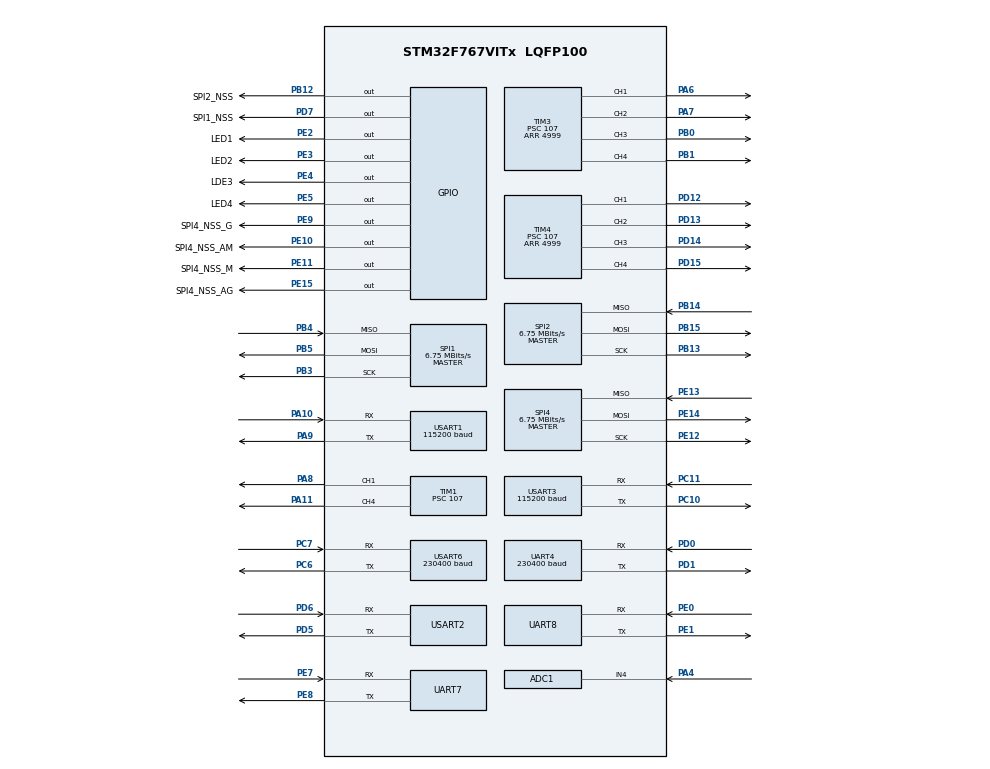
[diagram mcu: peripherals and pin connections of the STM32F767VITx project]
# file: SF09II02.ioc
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ADC1.Channel-0\#ChannelRegularConversion=ADC_CHANNEL_4
ADC1.NbrOfConversionFlag=1
ADC1.Rank-0\#ChannelRegularConversion=1
ADC1.SamplingTime-0\#ChannelRegularConversion=ADC_SAMPLETIME_3CYCLES
ADC1.master=1
Dma.ADC1.0.Direction=DMA_PERIPH_TO_MEMORY
Dma.ADC1.0.FIFOMode=DMA_FIFOMODE_DISABLE
Dma.ADC1.0.Instance=DMA2_Stream0
Dma.ADC1.0.MemDataAlignment=DMA_MDATAALIGN_HALFWORD
Dma.ADC1.0.MemInc=DMA_MINC_ENABLE
Dma.ADC1.0.Mode=DMA_NORMAL
Dma.ADC1.0.PeriphDataAlignment=DMA_PDATAALIGN_HALFWORD
Dma.ADC1.0.PeriphInc=DMA_PINC_DISABLE
Dma.ADC1.0.Priority=DMA_PRIORITY_LOW
Dma.Request0=ADC1
Dma.Request1=UART8_RX
Dma.Request10=UART4_RX
Dma.Request11=UART4_TX
Dma.Request2=USART1_RX
Dma.Request3=USART2_RX
Dma.Request4=USART3_RX
Dma.Request5=USART3_TX
Dma.Request6=USART6_RX
Dma.Request7=USART6_TX
Dma.Request8=UART8_TX
Dma.Request9=USART1_TX
Dma.UART4_RX.10.Direction=DMA_PERIPH_TO_MEMORY
Dma.UART4_RX.10.FIFOMode=DMA_FIFOMODE_DISABLE
Dma.UART4_RX.10.Instance=DMA1_Stream2
Dma.UART4_RX.10.MemDataAlignment=DMA_MDATAALIGN_BYTE
Dma.UART4_RX.10.MemInc=DMA_MINC_ENABLE
Dma.UART4_RX.10.Mode=DMA_NORMAL
Dma.UART4_RX.10.PeriphDataAlignment=DMA_PDATAALIGN_BYTE
Dma.UART4_RX.10.PeriphInc=DMA_PINC_DISABLE
Dma.UART4_RX.10.Priority=DMA_PRIORITY_LOW
Dma.UART4_TX.11.Direction=DMA_MEMORY_TO_PERIPH
Dma.UART4_TX.11.FIFOMode=DMA_FIFOMODE_DISABLE
Dma.UART4_TX.11.Instance=DMA1_Stream4
Dma.UART4_TX.11.MemDataAlignment=DMA_MDATAALIGN_BYTE
Dma.UART4_TX.11.MemInc=DMA_MINC_ENABLE
Dma.UART4_TX.11.Mode=DMA_NORMAL
Dma.UART4_TX.11.PeriphDataAlignment=DMA_PDATAALIGN_BYTE
Dma.UART4_TX.11.PeriphInc=DMA_PINC_DISABLE
Dma.UART4_TX.11.Priority=DMA_PRIORITY_LOW
Dma.UART8_RX.1.Direction=DMA_PERIPH_TO_MEMORY
Dma.UART8_RX.1.FIFOMode=DMA_FIFOMODE_DISABLE
Dma.UART8_RX.1.Instance=DMA1_Stream6
Dma.UART8_RX.1.MemDataAlignment=DMA_MDATAALIGN_BYTE
Dma.UART8_RX.1.MemInc=DMA_MINC_ENABLE
Dma.UART8_RX.1.Mode=DMA_NORMAL
Dma.UART8_RX.1.PeriphDataAlignment=DMA_PDATAALIGN_BYTE
Dma.UART8_RX.1.PeriphInc=DMA_PINC_DISABLE
Dma.UART8_RX.1.Priority=DMA_PRIORITY_LOW
Dma.UART8_TX.8.Direction=DMA_MEMORY_TO_PERIPH
Dma.UART8_TX.8.FIFOMode=DMA_FIFOMODE_DISABLE
Dma.UART8_TX.8.Instance=DMA1_Stream0
Dma.UART8_TX.8.MemDataAlignment=DMA_MDATAALIGN_BYTE
Dma.UART8_TX.8.MemInc=DMA_MINC_ENABLE
Dma.UART8_TX.8.Mode=DMA_NORMAL
Dma.UART8_TX.8.PeriphDataAlignment=DMA_PDATAALIGN_BYTE
Dma.UART8_TX.8.PeriphInc=DMA_PINC_DISABLE
Dma.UART8_TX.8.Priority=DMA_PRIORITY_LOW
Dma.USART1_RX.2.Direction=DMA_PERIPH_TO_MEMORY
Dma.USART1_RX.2.FIFOMode=DMA_FIFOMODE_DISABLE
Dma.USART1_RX.2.Instance=DMA2_Stream2
Dma.USART1_RX.2.MemDataAlignment=DMA_MDATAALIGN_BYTE
Dma.USART1_RX.2.MemInc=DMA_MINC_ENABLE
Dma.USART1_RX.2.Mode=DMA_NORMAL
Dma.USART1_RX.2.PeriphDataAlignment=DMA_PDATAALIGN_BYTE
Dma.USART1_RX.2.PeriphInc=DMA_PINC_DISABLE
Dma.USART1_RX.2.Priority=DMA_PRIORITY_LOW
Dma.USART1_TX.9.Direction=DMA_MEMORY_TO_PERIPH
Dma.USART1_TX.9.FIFOMode=DMA_FIFOMODE_DISABLE
Dma.USART1_TX.9.Instance=DMA2_Stream7
Dma.USART1_TX.9.MemDataAlignment=DMA_MDATAALIGN_BYTE
Dma.USART1_TX.9.MemInc=DMA_MINC_ENABLE
Dma.USART1_TX.9.Mode=DMA_NORMAL
Dma.USART1_TX.9.PeriphDataAlignment=DMA_PDATAALIGN_BYTE
Dma.USART1_TX.9.PeriphInc=DMA_PINC_DISABLE
Dma.USART1_TX.9.Priority=DMA_PRIORITY_LOW
Dma.USART2_RX.3.Direction=DMA_PERIPH_TO_MEMORY
Dma.USART2_RX.3.FIFOMode=DMA_FIFOMODE_DISABLE
Dma.USART2_RX.3.Instance=DMA1_Stream5
Dma.USART2_RX.3.MemDataAlignment=DMA_MDATAALIGN_BYTE
Dma.USART2_RX.3.MemInc=DMA_MINC_ENABLE
Dma.USART2_RX.3.Mode=DMA_NORMAL
Dma.USART2_RX.3.PeriphDataAlignment=DMA_PDATAALIGN_BYTE
Dma.USART2_RX.3.PeriphInc=DMA_PINC_DISABLE
Dma.USART2_RX.3.Priority=DMA_PRIORITY_LOW
Dma.USART3_RX.4.Direction=DMA_PERIPH_TO_MEMORY
Dma.USART3_RX.4.FIFOMode=DMA_FIFOMODE_DISABLE
Dma.USART3_RX.4.Instance=DMA1_Stream1
Dma.USART3_RX.4.MemDataAlignment=DMA_MDATAALIGN_BYTE
Dma.USART3_RX.4.MemInc=DMA_MINC_ENABLE
Dma.USART3_RX.4.Mode=DMA_NORMAL
Dma.USART3_RX.4.PeriphDataAlignment=DMA_PDATAALIGN_BYTE
Dma.USART3_RX.4.PeriphInc=DMA_PINC_DISABLE
Dma.USART3_RX.4.Priority=DMA_PRIORITY_LOW
Dma.USART3_TX.5.Direction=DMA_MEMORY_TO_PERIPH
Dma.USART3_TX.5.FIFOMode=DMA_FIFOMODE_DISABLE
Dma.USART3_TX.5.Instance=DMA1_Stream3
Dma.USART3_TX.5.MemDataAlignment=DMA_MDATAALIGN_BYTE
Dma.USART3_TX.5.MemInc=DMA_MINC_ENABLE
Dma.USART3_TX.5.Mode=DMA_NORMAL
Dma.USART3_TX.5.PeriphDataAlignment=DMA_PDATAALIGN_BYTE
Dma.USART3_TX.5.PeriphInc=DMA_PINC_DISABLE
Dma.USART3_TX.5.Priority=DMA_PRIORITY_LOW
Dma.USART6_RX.6.Direction=DMA_PERIPH_TO_MEMORY
Dma.USART6_RX.6.FIFOMode=DMA_FIFOMODE_DISABLE
Dma.USART6_RX.6.Instance=DMA2_Stream1
Dma.USART6_RX.6.MemDataAlignment=DMA_MDATAALIGN_BYTE
Dma.USART6_RX.6.MemInc=DMA_MINC_ENABLE
Dma.USART6_RX.6.Mode=DMA_NORMAL
Dma.USART6_RX.6.PeriphDataAlignment=DMA_PDATAALIGN_BYTE
Dma.USART6_RX.6.PeriphInc=DMA_PINC_DISABLE
Dma.USART6_RX.6.Priority=DMA_PRIORITY_LOW
Dma.USART6_TX.7.Direction=DMA_MEMORY_TO_PERIPH
Dma.USART6_TX.7.FIFOMode=DMA_FIFOMODE_DISABLE
Dma.USART6_TX.7.Instance=DMA2_Stream6
Dma.USART6_TX.7.MemDataAlignment=DMA_MDATAALIGN_BYTE
Dma.USART6_TX.7.MemInc=DMA_MINC_ENABLE
Dma.USART6_TX.7.Mode=DMA_NORMAL
Dma.USART6_TX.7.PeriphDataAlignment=DMA_PDATAALIGN_BYTE
Dma.USART6_TX.7.PeriphInc=DMA_PINC_DISABLE
Dma.USART6_TX.7.Priority=DMA_PRIORITY_LOW
FREERTOS.HEAP_NUMBER=3
FREERTOS.Tasks01=defaultTask,24,128,StartDefaultTask,Default,NULL,Dynamic,NULL,NULL
Mcu.Family=STM32F7
Mcu.Name=STM32F767VITx
Mcu.Package=LQFP100
NVIC.DMA1_Stream0_IRQn=true\:5\:0\:true\:false\:false\:false\:false\:true
NVIC.DMA1_Stream1_IRQn=true\:5\:0\:true\:false\:false\:false\:false\:false
NVIC.DMA1_Stream2_IRQn=true\:5\:0\:true\:false\:false\:false\:false\:true
NVIC.DMA1_Stream3_IRQn=true\:5\:0\:true\:false\:false\:false\:false\:false
NVIC.DMA1_Stream4_IRQn=true\:5\:0\:true\:false\:false\:false\:false\:true
NVIC.DMA1_Stream5_IRQn=true\:5\:0\:true\:false\:false\:false\:false\:true
NVIC.DMA1_Stream6_IRQn=true\:5\:0\:true\:false\:false\:false\:false\:true
NVIC.DMA2_Stream0_IRQn=true\:5\:0\:true\:false\:false\:false\:false\:true
NVIC.DMA2_Stream1_IRQn=true\:5\:0\:true\:false\:false\:false\:false\:true
NVIC.DMA2_Stream2_IRQn=true\:5\:0\:true\:false\:false\:false\:false\:false
NVIC.DMA2_Stream6_IRQn=true\:5\:0\:true\:false\:false\:false\:false\:true
NVIC.DMA2_Stream7_IRQn=true\:5\:0\:true\:false\:false\:false\:false\:false
NVIC.PriorityGroup=NVIC_PRIORITYGROUP_4
NVIC.TIM5_IRQn=true\:5\:0\:true\:false\:false\:true\:true\:true
NVIC.TIM7_IRQn=true\:0\:0\:false\:false\:true\:false\:false\:true
NVIC.TimeBase=TIM7_IRQn
NVIC.TimeBaseIP=TIM7
NVIC.UART4_IRQn=true\:5\:0\:true\:false\:false\:false\:true\:true
NVIC.UART7_IRQn=true\:5\:0\:false\:false\:false\:false\:true\:true
NVIC.UART8_IRQn=true\:5\:0\:true\:false\:false\:false\:true\:true
NVIC.USART1_IRQn=true\:5\:0\:true\:false\:false\:false\:true\:false
NVIC.USART2_IRQn=true\:5\:0\:true\:false\:false\:false\:true\:true
NVIC.USART3_IRQn=true\:5\:0\:true\:false\:false\:false\:true\:false
NVIC.USART6_IRQn=true\:5\:0\:true\:false\:false\:false\:true\:true
PA10.Mode=Asynchronous
PA10.Signal=USART1_RX
PA11.Signal=S_TIM1_CH4
PA13.Mode=Serial_Wire
PA13.Signal=SYS_JTMS-SWDIO
PA14.Mode=Serial_Wire
PA14.Signal=SYS_JTCK-SWCLK
PA4.Signal=ADCx_IN4
PA6.Signal=S_TIM3_CH1
PA7.Signal=S_TIM3_CH2
PA8.Signal=S_TIM1_CH1
PA9.Mode=Asynchronous
PA9.Signal=USART1_TX
PB0.Signal=S_TIM3_CH3
PB1.Signal=S_TIM3_CH4
PB12.GPIO_Label=SPI2_NSS
PB12.GPIO_Speed=GPIO_SPEED_FREQ_HIGH
PB12.PinState=GPIO_PIN_SET
PB12.Signal=GPIO_Output
PB13.Mode=Full_Duplex_Master
PB13.Signal=SPI2_SCK
PB14.Mode=Full_Duplex_Master
PB14.Signal=SPI2_MISO
PB15.Mode=Full_Duplex_Master
PB15.Signal=SPI2_MOSI
PB3.Mode=Full_Duplex_Master
PB3.Signal=SPI1_SCK
PB4.Mode=Full_Duplex_Master
PB4.Signal=SPI1_MISO
PB5.Mode=Full_Duplex_Master
PB5.Signal=SPI1_MOSI
PC10.Mode=Asynchronous
PC10.Signal=USART3_TX
PC11.Mode=Asynchronous
PC11.Signal=USART3_RX
PC6.Mode=Asynchronous
PC6.Signal=USART6_TX
PC7.Mode=Asynchronous
PC7.Signal=USART6_RX
PD0.Mode=Asynchronous
PD0.Signal=UART4_RX
PD1.Mode=Asynchronous
PD1.Signal=UART4_TX
PD12.Signal=S_TIM4_CH1
PD13.Signal=S_TIM4_CH2
PD14.Signal=S_TIM4_CH3
PD15.Signal=S_TIM4_CH4
PD5.Mode=Asynchronous
PD5.Signal=USART2_TX
PD6.Mode=Asynchronous
PD6.Signal=USART2_RX
PD7.GPIO_Label=SPI1_NSS
PD7.GPIO_Speed=GPIO_SPEED_FREQ_HIGH
PD7.PinState=GPIO_PIN_SET
PD7.Signal=GPIO_Output
PE0.Mode=Asynchronous
PE0.Signal=UART8_RX
PE1.Mode=Asynchronous
PE1.Signal=UART8_TX
PE10.GPIO_Label=SPI4_NSS_AM
PE10.GPIO_Speed=GPIO_SPEED_FREQ_HIGH
PE10.PinState=GPIO_PIN_SET
PE10.Signal=GPIO_Output
PE11.GPIO_Label=SPI4_NSS_M
PE11.GPIO_Speed=GPIO_SPEED_FREQ_HIGH
PE11.PinState=GPIO_PIN_SET
PE11.Signal=GPIO_Output
PE12.Mode=Full_Duplex_Master
PE12.Signal=SPI4_SCK
PE13.Mode=Full_Duplex_Master
PE13.Signal=SPI4_MISO
PE14.Mode=Full_Duplex_Master
PE14.Signal=SPI4_MOSI
PE15.GPIO_Label=SPI4_NSS_AG
PE15.GPIO_Speed=GPIO_SPEED_FREQ_HIGH
PE15.PinState=GPIO_PIN_SET
PE15.Signal=GPIO_Output
PE2.GPIO_Label=LED1
PE2.PinState=GPIO_PIN_SET
PE2.Signal=GPIO_Output
PE3.GPIO_Label=LED2
PE3.PinState=GPIO_PIN_SET
PE3.Signal=GPIO_Output
PE4.GPIO_Label=LDE3
PE4.PinState=GPIO_PIN_SET
PE4.Signal=GPIO_Output
PE5.GPIO_Label=LED4
PE5.PinState=GPIO_PIN_SET
PE5.Signal=GPIO_Output
PE7.Mode=Asynchronous
PE7.Signal=UART7_RX
PE8.Mode=Asynchronous
PE8.Signal=UART7_TX
PE9.GPIO_Label=SPI4_NSS_G
PE9.GPIO_Speed=GPIO_SPEED_FREQ_HIGH
PE9.PinState=GPIO_PIN_SET
PE9.Signal=GPIO_Output
PH0/OSC_IN.Mode=HSE-External-Oscillator
PH0/OSC_IN.Signal=RCC_OSC_IN
PH1/OSC_OUT.Mode=HSE-External-Oscillator
PH1/OSC_OUT.Signal=RCC_OSC_OUT
ProjectManager.HeapSize=0x200
ProjectManager.StackSize=0x400
ProjectManager.TargetToolchain=STM32CubeIDE
RCC.AHBFreq_Value=216000000
RCC.APB1CLKDivider=RCC_HCLK_DIV4
RCC.APB1Freq_Value=54000000
RCC.APB1TimFreq_Value=108000000
RCC.APB2CLKDivider=RCC_HCLK_DIV4
RCC.APB2Freq_Value=54000000
RCC.APB2TimFreq_Value=108000000
RCC.CortexFreq_Value=216000000
RCC.HCLKFreq_Value=216000000
RCC.HSE_VALUE=25000000
RCC.HSI_VALUE=16000000
RCC.LSE_VALUE=32768
RCC.PLLM=25
RCC.PLLN=432
RCC.PLLSourceVirtual=RCC_PLLSOURCE_HSE
RCC.SYSCLKFreq_VALUE=216000000
RCC.SYSCLKSource=RCC_SYSCLKSOURCE_PLLCLK
RCC.USBFreq_Value=216000000
RCC.VCOOutputFreq_Value=432000000
SH.ADCx_IN4.0=ADC1_IN4,IN4
SH.S_TIM1_CH1.0=TIM1_CH1,PWM Generation1 CH1
SH.S_TIM1_CH4.0=TIM1_CH4,PWM Generation4 CH4
SH.S_TIM3_CH1.0=TIM3_CH1,PWM Generation1 CH1
SH.S_TIM3_CH2.0=TIM3_CH2,PWM Generation2 CH2
SH.S_TIM3_CH3.0=TIM3_CH3,PWM Generation3 CH3
SH.S_TIM3_CH4.0=TIM3_CH4,PWM Generation4 CH4
SH.S_TIM4_CH1.0=TIM4_CH1,PWM Generation1 CH1
SH.S_TIM4_CH2.0=TIM4_CH2,PWM Generation2 CH2
SH.S_TIM4_CH3.0=TIM4_CH3,PWM Generation3 CH3
SH.S_TIM4_CH4.0=TIM4_CH4,PWM Generation4 CH4
SPI1.BaudRatePrescaler=SPI_BAUDRATEPRESCALER_8
SPI1.CLKPhase=SPI_PHASE_2EDGE
SPI1.CLKPolarity=SPI_POLARITY_HIGH
SPI1.CalculateBaudRate=6.75 MBits/s
SPI1.DataSize=SPI_DATASIZE_8BIT
SPI1.Direction=SPI_DIRECTION_2LINES
SPI1.Mode=SPI_MODE_MASTER
SPI1.VirtualType=VM_MASTER
SPI2.BaudRatePrescaler=SPI_BAUDRATEPRESCALER_8
SPI2.CLKPhase=SPI_PHASE_2EDGE
SPI2.CLKPolarity=SPI_POLARITY_HIGH
SPI2.CalculateBaudRate=6.75 MBits/s
SPI2.DataSize=SPI_DATASIZE_8BIT
SPI2.Direction=SPI_DIRECTION_2LINES
SPI2.Mode=SPI_MODE_MASTER
SPI2.VirtualType=VM_MASTER
SPI4.BaudRatePrescaler=SPI_BAUDRATEPRESCALER_8
SPI4.CLKPhase=SPI_PHASE_2EDGE
SPI4.CLKPolarity=SPI_POLARITY_HIGH
SPI4.CalculateBaudRate=6.75 MBits/s
SPI4.DataSize=SPI_DATASIZE_8BIT
SPI4.Direction=SPI_DIRECTION_2LINES
SPI4.Mode=SPI_MODE_MASTER
SPI4.VirtualType=VM_MASTER
TIM1.Channel-PWM\ Generation1\ CH1=TIM_CHANNEL_1
TIM1.Channel-PWM\ Generation4\ CH4=TIM_CHANNEL_4
TIM1.Period=999
TIM1.Prescaler=107
TIM2.Prescaler=107
TIM3.Channel-PWM\ Generation1\ CH1=TIM_CHANNEL_1
TIM3.Channel-PWM\ Generation2\ CH2=TIM_CHANNEL_2
TIM3.Channel-PWM\ Generation3\ CH3=TIM_CHANNEL_3
TIM3.Channel-PWM\ Generation4\ CH4=TIM_CHANNEL_4
TIM3.Period=4999
TIM3.Prescaler=107
TIM4.Channel-PWM\ Generation1\ CH1=TIM_CHANNEL_1
TIM4.Channel-PWM\ Generation2\ CH2=TIM_CHANNEL_2
TIM4.Channel-PWM\ Generation3\ CH3=TIM_CHANNEL_3
TIM4.Channel-PWM\ Generation4\ CH4=TIM_CHANNEL_4
TIM4.Period=4999
TIM4.Prescaler=107
TIM5.Period=999
TIM5.Prescaler=107
UART4.BaudRate=230400
UART4.DMADisableonRxErrorParam=UART_ADVFEATURE_DMA_DISABLEONRXERROR
UART4.OverrunDisableParam=UART_ADVFEATURE_OVERRUN_DISABLE
UART7.DMADisableonRxErrorParam=UART_ADVFEATURE_DMA_DISABLEONRXERROR
UART7.OverrunDisableParam=UART_ADVFEATURE_OVERRUN_DISABLE
UART8.DMADisableonRxErrorParam=UART_ADVFEATURE_DMA_DISABLEONRXERROR
UART8.OverrunDisableParam=UART_ADVFEATURE_OVERRUN_DISABLE
USART1.BaudRate=115200
USART1.DMADisableonRxErrorParam=ADVFEATURE_DMA_DISABLEONRXERROR
USART1.OverrunDisableParam=ADVFEATURE_OVERRUN_DISABLE
USART1.Parity=PARITY_NONE
USART1.StopBits=STOPBITS_1
USART1.VirtualMode-Asynchronous=VM_ASYNC
USART1.WordLength=WORDLENGTH_8B
USART2.DMADisableonRxErrorParam=ADVFEATURE_DMA_DISABLEONRXERROR
USART2.OverrunDisableParam=ADVFEATURE_OVERRUN_DISABLE
USART2.VirtualMode-Asynchronous=VM_ASYNC
USART3.BaudRate=115200
USART3.DMADisableonRxErrorParam=ADVFEATURE_DMA_DISABLEONRXERROR
USART3.OverrunDisableParam=ADVFEATURE_OVERRUN_DISABLE
USART3.VirtualMode-Asynchronous=VM_ASYNC
USART6.BaudRate=230400
USART6.DMADisableonRxErrorParam=ADVFEATURE_DMA_DISABLEONRXERROR
USART6.OverrunDisableParam=ADVFEATURE_OVERRUN_DISABLE
USART6.VirtualMode=VM_ASYNC
VP_FREERTOS_VS_CMSIS_V2.Mode=CMSIS_V2
VP_SYS_VS_tim7.Mode=TIM7
VP_TIM1_VS_ClockSourceINT.Mode=Internal
VP_TIM2_VS_ClockSourceINT.Mode=Internal
VP_TIM3_VS_ClockSourceINT.Mode=Internal
VP_TIM4_VS_ClockSourceINT.Mode=Internal
VP_TIM5_VS_ClockSourceINT.Mode=Internal
board=custom

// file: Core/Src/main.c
/* USER CODE BEGIN Header */
/**
  ******************************************************************************
  * @file           : main.c
  * @brief          : Main program body
  ******************************************************************************
  * @attention
  *
  * <h2><center>&copy; Copyright (c) 2020 STMicroelectronics.
  * All rights reserved.</center></h2>
  *
  * This software component is licensed by ST under BSD 3-Clause license,
  * the "License"; You may not use this file except in compliance with the
  * License. You may obtain a copy of the License at:
  *                        opensource.org/licenses/BSD-3-Clause
  *
  ******************************************************************************
  */
/* USER CODE END Header */
#include "main.h"
#include "cmsis_os.h"
#include "adc.h"
#include "dma.h"
#include "spi.h"
#include "tim.h"
#include "usart.h"
#include "gpio.h"

void SystemClock_Config(void);
void MX_FREERTOS_Init(void);

int main(void)
{

  /* MCU Configuration--------------------------------------------------------*/

  /* Reset of all peripherals, Initializes the Flash interface and the Systick. */
  HAL_Init();

  /* Configure the system clock */
  SystemClock_Config();

  /* Initialize all configured peripherals */
  MX_GPIO_Init();
  MX_DMA_Init();
  MX_ADC1_Init();
  MX_SPI2_Init();
  MX_SPI4_Init();
  MX_TIM1_Init();
  MX_TIM2_Init();
  MX_TIM3_Init();
  MX_TIM4_Init();
  MX_UART4_Init();
  MX_UART8_Init();
  MX_USART1_UART_Init();
  MX_USART2_UART_Init();
  MX_USART3_UART_Init();
  MX_USART6_UART_Init();
  MX_SPI1_Init();
  MX_TIM5_Init();
  MX_UART7_Init();

  /* Init scheduler */
  osKernelInitialize();  /* Call init function for freertos objects (in freertos.c) */
  MX_FREERTOS_Init();
  /* Start scheduler */
  osKernelStart();

  /* We should never get here as control is now taken by the scheduler */
  /* Infinite loop */
  while (1)
  {

  }
}

void SystemClock_Config(void)
{
  LL_FLASH_SetLatency(LL_FLASH_LATENCY_7);
  while(LL_FLASH_GetLatency()!= LL_FLASH_LATENCY_7)
  {
  }
  LL_PWR_SetRegulVoltageScaling(LL_PWR_REGU_VOLTAGE_SCALE1);
  LL_PWR_EnableOverDriveMode();
  LL_RCC_HSE_Enable();

   /* Wait till HSE is ready */
  while(LL_RCC_HSE_IsReady() != 1)
  {

  }
  LL_RCC_PLL_ConfigDomain_SYS(LL_RCC_PLLSOURCE_HSE, LL_RCC_PLLM_DIV_25, 432, LL_RCC_PLLP_DIV_2);
  LL_RCC_PLL_Enable();

   /* Wait till PLL is ready */
  while(LL_RCC_PLL_IsReady() != 1)
  {

  }
  LL_RCC_SetAHBPrescaler(LL_RCC_SYSCLK_DIV_1);
  LL_RCC_SetAPB1Prescaler(LL_RCC_APB1_DIV_4);
  LL_RCC_SetAPB2Prescaler(LL_RCC_APB2_DIV_4);
  LL_RCC_SetSysClkSource(LL_RCC_SYS_CLKSOURCE_PLL);

   /* Wait till System clock is ready */
  while(LL_RCC_GetSysClkSource() != LL_RCC_SYS_CLKSOURCE_STATUS_PLL)
  {

  }
  LL_SetSystemCoreClock(216000000);

   /* Update the time base */
  if (HAL_InitTick (TICK_INT_PRIORITY) != HAL_OK)
  {
    Error_Handler();
  }
  LL_RCC_SetUSARTClockSource(LL_RCC_USART1_CLKSOURCE_PCLK2);
  LL_RCC_SetUSARTClockSource(LL_RCC_USART2_CLKSOURCE_PCLK1);
  LL_RCC_SetUSARTClockSource(LL_RCC_USART3_CLKSOURCE_PCLK1);
  LL_RCC_SetUSARTClockSource(LL_RCC_USART6_CLKSOURCE_PCLK2);
  LL_RCC_SetUARTClockSource(LL_RCC_UART4_CLKSOURCE_PCLK1);
  LL_RCC_SetUARTClockSource(LL_RCC_UART7_CLKSOURCE_PCLK1);
  LL_RCC_SetUARTClockSource(LL_RCC_UART8_CLKSOURCE_PCLK1);
}

 /**
  * @brief  Period elapsed callback in non blocking mode
  * @note   This function is called  when TIM7 interrupt took place, inside
  * HAL_TIM_IRQHandler(). It makes a direct call to HAL_IncTick() to increment
  * a global variable "uwTick" used as application time base.
  * @param  htim : TIM handle
  * @retval None
  */
void HAL_TIM_PeriodElapsedCallback(TIM_HandleTypeDef *htim)
{
  if (htim->Instance == TIM7) {
    HAL_IncTick();
  }
}

void Error_Handler(void)
{
}

/************************ (C) COPYRIGHT STMicroelectronics *****END OF FILE****/

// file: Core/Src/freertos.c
/* USER CODE BEGIN Header */
/**
  ******************************************************************************
  * File Name          : freertos.c
  * Description        : Code for freertos applications
  ******************************************************************************
  * @attention
  *
  * <h2><center>&copy; Copyright (c) 2020 STMicroelectronics.
  * All rights reserved.</center></h2>
  *
  * This software component is licensed by ST under Ultimate Liberty license
  * SLA0044, the "License"; You may not use this file except in compliance with
  * the License. You may obtain a copy of the License at:
  *                             www.st.com/SLA0044
  *
  ******************************************************************************
  */
/* USER CODE END Header */

#include "FreeRTOS.h"
#include "task.h"
#include "main.h"
#include "cmsis_os.h"

/* USER CODE BEGIN Includes */
#include "system/system.hpp"
/* USER CODE END Includes */

/* Definitions for defaultTask */
osThreadId_t defaultTaskHandle;
const osThreadAttr_t defaultTask_attributes = {
  .name = "defaultTask",
  .priority = (osPriority_t) osPriorityNormal,
  .stack_size = 128 * 4
};

void StartDefaultTask(void *argument);

void MX_FREERTOS_Init(void); /* (MISRA C 2004 rule 8.1) */

void MX_FREERTOS_Init(void) {
  /* USER CODE BEGIN Init */
	LL_SPI_Enable(SPI4);
	LL_SPI_SetRxFIFOThreshold(SPI4, LL_SPI_RX_FIFO_TH_QUARTER);
	HAL_Delay(200);
	LL_TIM_EnableCounter(TIM2);		//启动计时�??,单位为us
  /* USER CODE END Init */

  /* Create the thread(s) */
  /* creation of defaultTask */
  defaultTaskHandle = osThreadNew(StartDefaultTask, NULL, &defaultTask_attributes);

  /* USER CODE BEGIN RTOS_THREADS */
  /* add threads, ... */
  mySystemInit();
  /* USER CODE END RTOS_THREADS */

}

void StartDefaultTask(void *argument)
{
  /* USER CODE BEGIN StartDefaultTask */
  /* Infinite loop */
	LL_TIM_ClearFlag_UPDATE(TIM5);
	LL_TIM_EnableCounter(TIM5);
	LL_TIM_EnableIT_UPDATE(TIM5);
  for(;;)
  {
    osDelay(1);
  }
  /* USER CODE END StartDefaultTask */
}

/************************ (C) COPYRIGHT STMicroelectronics *****END OF FILE****/
